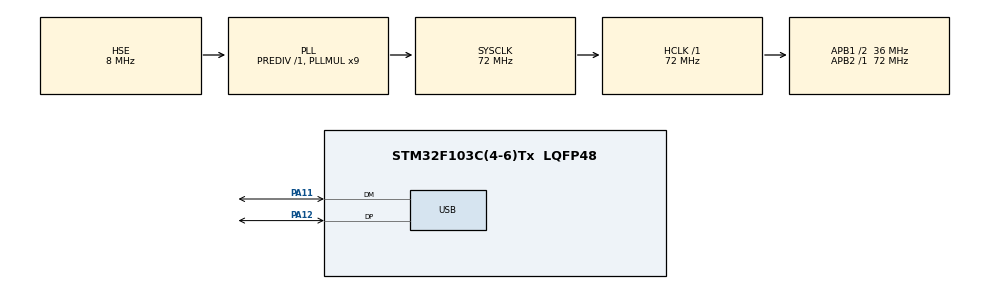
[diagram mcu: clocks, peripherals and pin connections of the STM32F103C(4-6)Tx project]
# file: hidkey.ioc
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Mcu.Family=STM32F1
Mcu.Name=STM32F103C(4-6)Tx
Mcu.Package=LQFP48
NVIC.PriorityGroup=NVIC_PRIORITYGROUP_4
NVIC.USB_LP_CAN1_RX0_IRQn=true\:0\:0\:false\:false\:true\:false\:true
PA11.Mode=Device
PA11.Signal=USB_DM
PA12.Mode=Device
PA12.Signal=USB_DP
PA13.Mode=Serial_Wire
PA13.Signal=SYS_JTMS-SWDIO
PA14.Mode=Serial_Wire
PA14.Signal=SYS_JTCK-SWCLK
PD0-OSC_IN.Mode=HSE-External-Oscillator
PD0-OSC_IN.Signal=RCC_OSC_IN
PD1-OSC_OUT.Mode=HSE-External-Oscillator
PD1-OSC_OUT.Signal=RCC_OSC_OUT
ProjectManager.HeapSize=0x200
ProjectManager.StackSize=0x1000
ProjectManager.TargetToolchain=STM32CubeIDE
RCC.AHBFreq_Value=72000000
RCC.APB1CLKDivider=RCC_HCLK_DIV2
RCC.APB1Freq_Value=36000000
RCC.APB1TimFreq_Value=72000000
RCC.APB2Freq_Value=72000000
RCC.APB2TimFreq_Value=72000000
RCC.HCLKFreq_Value=72000000
RCC.PLLMUL=RCC_PLL_MUL9
RCC.SYSCLKFreq_VALUE=72000000
RCC.SYSCLKSource=RCC_SYSCLKSOURCE_PLLCLK
RCC.USBFreq_Value=48000000
RCC.USBPrescaler=RCC_USBCLKSOURCE_PLL_DIV1_5
USB_DEVICE.CLASS_NAME_FS=HID
USB_DEVICE.VirtualMode=Hid
USB_DEVICE.VirtualModeFS=Hid_FS
VP_USB_DEVICE_VS_USB_DEVICE_HID_FS.Mode=HID_FS
board=custom

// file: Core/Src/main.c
/* USER CODE BEGIN Header */
/**
  ******************************************************************************
  * @file           : main.c
  * @brief          : Main program body
  ******************************************************************************
  * @attention
  *
  * <h2><center>&copy; Copyright (c) 2019 STMicroelectronics.
  * All rights reserved.</center></h2>
  *
  * This software component is licensed by ST under BSD 3-Clause license,
  * the "License"; You may not use this file except in compliance with the
  * License. You may obtain a copy of the License at:
  *                        opensource.org/licenses/BSD-3-Clause
  *
  ******************************************************************************
  */
/* USER CODE END Header */

#include "main.h"
#include "usb_device.h"
#include "gpio.h"

/* USER CODE BEGIN Includes */

#include "usbd_hid.h"
/* USER CODE END Includes */

/* USER CODE BEGIN PD */
	uint8_t txbuffer[8]= {0x00,0x00,0x00,0x00,0x00,0x00,0x00,0x00};
	uint8_t	sendbuffer[8]={0x00,0x00,0x2c,0x00,0x00,0x00,0x00,0x00};
	uint8_t buffer[9] = {0x00, 0x00, 0x00, 0x00, 0x00, 0x00, 0x00, 0x00};
	uint8_t report[4]={0,10,0,0};
/* USER CODE END PD */

void SystemClock_Config(void);

int main(void)
{
  /* USER CODE BEGIN 1 */
	 /*
	 * buffer[0] - bit0: Left CTRL
	 *           -bit1: Left SHIFT
	 *           -bit2: Left ALT
	 *           -bit3: Left GUI
	 *           -bit4: Right CTRL
	 *           -bit5: Right SHIFT
	 *           -bit6: Right ALT
	 *           -bit7: Right GUI
	 * buffer[1] - Padding = Always 0x00
	 * buffer[2] - Key 1
	 * buffer[3] - Key 2
	 * buffer[4] - Key 3
	 * buffer[5] - Key 4
	 * buffer[6] - Key 5
	 * buffer[7] - Key 6
	 */
  /* USER CODE END 1 */

  /* MCU Configuration--------------------------------------------------------*/

  /* Reset of all peripherals, Initializes the Flash interface and the Systick. */
  HAL_Init();

  /* Configure the system clock */
  SystemClock_Config();

  /* Initialize all configured peripherals */

  /* USER CODE BEGIN 2 */
  MX_GPIO_Init();
  MX_USB_DEVICE_Init();

  /* USER CODE END 2 */

  /* Infinite loop */
  /* USER CODE BEGIN WHILE */
  while (1)//无限循环
  {
    /* USER CODE END WHILE */

    /* USER CODE BEGIN 3 */
	HAL_Delay(100); //延迟 100ms
	HAL_Delay(100); //延迟 100ms
	HAL_Delay(100); //延迟 100ms
	USBD_HID_SendReport(&hUsbDeviceFS,report,4);//让鼠标右移4个像素
  }
  /* USER CODE END 3 */
}

void SystemClock_Config(void)
{
  RCC_OscInitTypeDef RCC_OscInitStruct = {0};
  RCC_ClkInitTypeDef RCC_ClkInitStruct = {0};
  RCC_PeriphCLKInitTypeDef PeriphClkInit = {0};

  /** Initializes the CPU, AHB and APB busses clocks
  */
  RCC_OscInitStruct.OscillatorType = RCC_OSCILLATORTYPE_HSE;
  RCC_OscInitStruct.HSEState = RCC_HSE_ON;
  RCC_OscInitStruct.HSEPredivValue = RCC_HSE_PREDIV_DIV1;
  RCC_OscInitStruct.HSIState = RCC_HSI_ON;
  RCC_OscInitStruct.PLL.PLLState = RCC_PLL_ON;
  RCC_OscInitStruct.PLL.PLLSource = RCC_PLLSOURCE_HSE;
  RCC_OscInitStruct.PLL.PLLMUL = RCC_PLL_MUL9;
  if (HAL_RCC_OscConfig(&RCC_OscInitStruct) != HAL_OK)
  {
    Error_Handler();
  }
  /** Initializes the CPU, AHB and APB busses clocks
  */
  RCC_ClkInitStruct.ClockType = RCC_CLOCKTYPE_HCLK|RCC_CLOCKTYPE_SYSCLK|RCC_CLOCKTYPE_PCLK1|RCC_CLOCKTYPE_PCLK2;
  RCC_ClkInitStruct.SYSCLKSource = RCC_SYSCLKSOURCE_PLLCLK;
  RCC_ClkInitStruct.AHBCLKDivider = RCC_SYSCLK_DIV1;
  RCC_ClkInitStruct.APB1CLKDivider = RCC_HCLK_DIV2;
  RCC_ClkInitStruct.APB2CLKDivider = RCC_HCLK_DIV1;

  if (HAL_RCC_ClockConfig(&RCC_ClkInitStruct, FLASH_LATENCY_2) != HAL_OK)
  {
    Error_Handler();
  }
  PeriphClkInit.PeriphClockSelection = RCC_PERIPHCLK_USB;
  PeriphClkInit.UsbClockSelection = RCC_USBCLKSOURCE_PLL_DIV1_5;
  if (HAL_RCCEx_PeriphCLKConfig(&PeriphClkInit) != HAL_OK)
  {
    Error_Handler();
  }
}

void Error_Handler(void)
{
}

/************************ (C) COPYRIGHT STMicroelectronics *****END OF FILE****/
